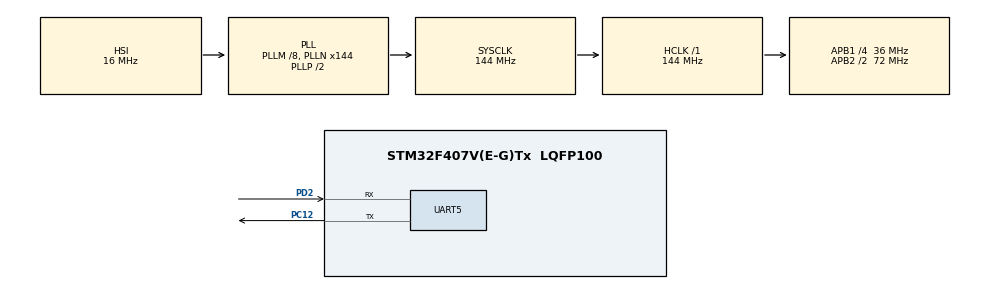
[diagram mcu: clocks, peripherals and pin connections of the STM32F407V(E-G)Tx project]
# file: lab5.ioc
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Mcu.Family=STM32F4
Mcu.Name=STM32F407V(E-G)Tx
Mcu.Package=LQFP100
NVIC.PriorityGroup=NVIC_PRIORITYGROUP_4
NVIC.RCC_IRQn=true\:0\:0\:false\:false\:true\:true\:false\:true
NVIC.TIM3_IRQn=true\:0\:0\:false\:false\:true\:true\:true\:true
NVIC.UART5_IRQn=true\:0\:0\:false\:false\:true\:true\:true\:true
PA13.Mode=Serial_Wire
PA13.Signal=SYS_JTMS-SWDIO
PA14.Mode=Serial_Wire
PA14.Signal=SYS_JTCK-SWCLK
PC12.Mode=Asynchronous
PC12.Signal=UART5_TX
PC14-OSC32_IN.Mode=LSE-External-Oscillator
PC14-OSC32_IN.Signal=RCC_OSC32_IN
PC15-OSC32_OUT.Mode=LSE-External-Oscillator
PC15-OSC32_OUT.Signal=RCC_OSC32_OUT
PD2.Mode=Asynchronous
PD2.Signal=UART5_RX
PH0-OSC_IN.Mode=HSE-External-Oscillator
PH0-OSC_IN.Signal=RCC_OSC_IN
PH1-OSC_OUT.Mode=HSE-External-Oscillator
PH1-OSC_OUT.Signal=RCC_OSC_OUT
ProjectManager.HeapSize=0x200
ProjectManager.StackSize=0x400
ProjectManager.TargetToolchain=STM32CubeIDE
RCC.48MHZClocksFreq_Value=72000000
RCC.AHBFreq_Value=144000000
RCC.APB1CLKDivider=RCC_HCLK_DIV4
RCC.APB1Freq_Value=36000000
RCC.APB1TimFreq_Value=72000000
RCC.APB2CLKDivider=RCC_HCLK_DIV2
RCC.APB2Freq_Value=72000000
RCC.APB2TimFreq_Value=144000000
RCC.CortexFreq_Value=144000000
RCC.HCLKFreq_Value=144000000
RCC.HSE_VALUE=25000000
RCC.HSI_VALUE=16000000
RCC.PLLM=8
RCC.PLLN=144
RCC.SYSCLKFreq_VALUE=144000000
RCC.SYSCLKSource=RCC_SYSCLKSOURCE_PLLCLK
RCC.VCOOutputFreq_Value=288000000
TIM3.Period=10000
TIM3.Prescaler=7200-1
UART5.VirtualMode=Asynchronous
VP_TIM3_VS_ClockSourceINT.Mode=Internal
board=custom

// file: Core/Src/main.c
/* USER CODE BEGIN Header */
/**
  ******************************************************************************
  * @file           : main.c
  * @brief          : Main program body
  ******************************************************************************
  * @attention
  *
  * Copyright (c) 2026 STMicroelectronics.
  * All rights reserved.
  *
  * This software is licensed under terms that can be found in the LICENSE file
  * in the root directory of this software component.
  * If no LICENSE file comes with this software, it is provided AS-IS.
  *
  ******************************************************************************
  */
/* USER CODE END Header */
#include "main.h"
#include "tim.h"
#include "usart.h"
#include "gpio.h"

/* USER CODE BEGIN PV */
volatile uint32_t current_time = 0;
volatile uint32_t previous_time = 0;
uint8_t uart_data[] = "Dzis Oleksiy, Group CI-41\r\n";

/* USER CODE END PV */

void SystemClock_Config(void);

int main(void)
{

  /* MCU Configuration--------------------------------------------------------*/

  /* Reset of all peripherals, Initializes the Flash interface and the Systick. */
  HAL_Init();

  /* Configure the system clock */
  SystemClock_Config();

  /* Initialize all configured peripherals */
  MX_GPIO_Init();
  MX_TIM3_Init();
  MX_UART5_Init();
  /* USER CODE BEGIN 2 */
  HAL_TIM_Base_Start_IT(&htim3);
  /* USER CODE END 2 */

  /* Infinite loop */
  /* USER CODE BEGIN WHILE */
  while (1)
  {
	  if ((current_time - previous_time) >= 2)
	  {
	      HAL_UART_Transmit_IT(&huart5, uart_data, sizeof(uart_data) - 1);
	      previous_time = current_time;
	  }
  }
  /* USER CODE END 3 */
}

void SystemClock_Config(void)
{
  RCC_OscInitTypeDef RCC_OscInitStruct = {0};
  RCC_ClkInitTypeDef RCC_ClkInitStruct = {0};

  /** Configure the main internal regulator output voltage
  */
  __HAL_RCC_PWR_CLK_ENABLE();
  __HAL_PWR_VOLTAGESCALING_CONFIG(PWR_REGULATOR_VOLTAGE_SCALE1);

  /** Initializes the RCC Oscillators according to the specified parameters
  * in the RCC_OscInitTypeDef structure.
  */
  RCC_OscInitStruct.OscillatorType = RCC_OSCILLATORTYPE_HSI;
  RCC_OscInitStruct.HSIState = RCC_HSI_ON;
  RCC_OscInitStruct.HSICalibrationValue = RCC_HSICALIBRATION_DEFAULT;
  RCC_OscInitStruct.PLL.PLLState = RCC_PLL_ON;
  RCC_OscInitStruct.PLL.PLLSource = RCC_PLLSOURCE_HSI;
  RCC_OscInitStruct.PLL.PLLM = 8;
  RCC_OscInitStruct.PLL.PLLN = 144;
  RCC_OscInitStruct.PLL.PLLP = RCC_PLLP_DIV2;
  RCC_OscInitStruct.PLL.PLLQ = 4;
  if (HAL_RCC_OscConfig(&RCC_OscInitStruct) != HAL_OK)
  {
    Error_Handler();
  }

  /** Initializes the CPU, AHB and APB buses clocks
  */
  RCC_ClkInitStruct.ClockType = RCC_CLOCKTYPE_HCLK|RCC_CLOCKTYPE_SYSCLK
                              |RCC_CLOCKTYPE_PCLK1|RCC_CLOCKTYPE_PCLK2;
  RCC_ClkInitStruct.SYSCLKSource = RCC_SYSCLKSOURCE_PLLCLK;
  RCC_ClkInitStruct.AHBCLKDivider = RCC_SYSCLK_DIV1;
  RCC_ClkInitStruct.APB1CLKDivider = RCC_HCLK_DIV4;
  RCC_ClkInitStruct.APB2CLKDivider = RCC_HCLK_DIV2;

  if (HAL_RCC_ClockConfig(&RCC_ClkInitStruct, FLASH_LATENCY_4) != HAL_OK)
  {
    Error_Handler();
  }
}

/* USER CODE BEGIN 4 */
void HAL_TIM_PeriodElapsedCallback(TIM_HandleTypeDef *htim)
{
     if (htim->Instance == TIM3)
    {
        current_time++;
    }
}
/* USER CODE END 4 */

void Error_Handler(void)
{
  __disable_irq();
  while (1)
  {
  }
}
